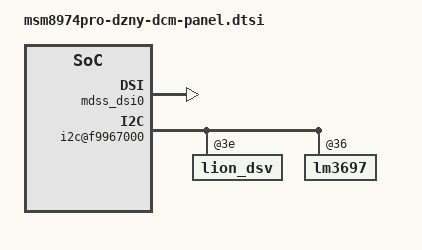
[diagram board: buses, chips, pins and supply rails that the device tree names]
/* Copyright (c) 2012, Code Aurora Forum. All rights reserved.
 *
 * This program is free software; you can redistribute it and/or modify
 * it under the terms of the GNU General Public License version 2 and
 * only version 2 as published by the Free Software Foundation.
 *
 * This program is distributed in the hope that it will be useful,
 * but WITHOUT ANY WARRANTY; without even the implied warranty of
 * MERCHANTABILITY or FITNESS FOR A PARTICULAR PURPOSE.  See the
 * GNU General Public License for more details.
 */


/*---------------------------------------------------------------------------
 * This file is autogenerated file using gcdb parser. Please do not edit it.
 * Update input XML file to add a new entry or update variable in this file
 * VERSION = "1.0"
 *---------------------------------------------------------------------------*/

&mdss_dsi0 {
	status = "ok";
};

&mdss_dsi1 {
	status = "disable";
};

&soc {
	mdss_mdp: qcom,mdss_mdp@fd900000 {

	/* Fudge factors */
	qcom,mdss-clk-factor = <7 5>;	/* 1.4 times */
	};

	i2c@f9967000 {
		lion_dsv@3e {
			status = "ok";
 		};
		lm3697@36 {
			status = "ok";
		};
	};
};


